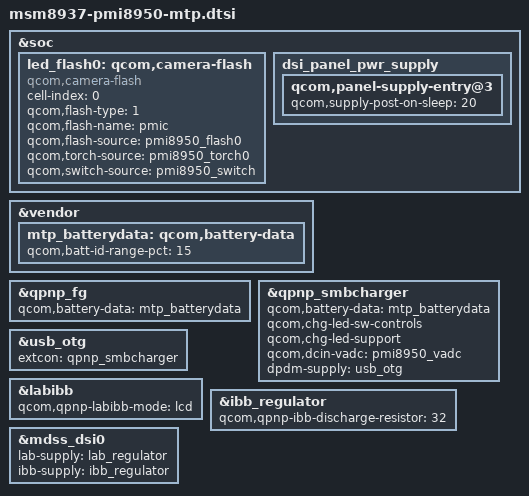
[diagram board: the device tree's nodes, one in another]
/*
 * Copyright (c) 2015-2016, 2018, The Linux Foundation. All rights reserved.
 *
 * This program is free software; you can redistribute it and/or modify
 * it under the terms of the GNU General Public License version 2 and
 * only version 2 as published by the Free Software Foundation.
 *
 * This program is distributed in the hope that it will be useful,
 * but WITHOUT ANY WARRANTY; without even the implied warranty of
 * MERCHANTABILITY or FITNESS FOR A PARTICULAR PURPOSE.  See the
 * GNU General Public License for more details.
 */

#include "pmi8950.dtsi"
#include "msm8937-mtp.dtsi"

&soc {
	led_flash0: qcom,camera-flash {
		cell-index = <0>;
		compatible = "qcom,camera-flash";
		qcom,flash-type = <1>;
		qcom,flash-name = "pmic";
		qcom,flash-source = <&pmi8950_flash0>;
		qcom,torch-source = <&pmi8950_torch0>;
		qcom,switch-source = <&pmi8950_switch>;
	};

	dsi_panel_pwr_supply: dsi_panel_pwr_supply {
		qcom,panel-supply-entry@3 {
			qcom,supply-post-on-sleep = <20>;
		};
	};
};

&vendor {
	mtp_batterydata: qcom,battery-data {
		qcom,batt-id-range-pct = <15>;
		#include "batterydata-oppo16061-sdi-2820mah.dtsi"
		#include "batterydata-oppo16061-lg-2820mah.dtsi"
		#include "batterydata-oppo16061-atl-2820mah.dtsi"
		#include "batterydata-oppo16061-non-std-2820mah.dtsi"
	};
};

&qpnp_fg {
	qcom,battery-data = <&mtp_batterydata>;
};

&qpnp_smbcharger {
	qcom,battery-data = <&mtp_batterydata>;
	qcom,chg-led-sw-controls;
	qcom,chg-led-support;
	qcom,dcin-vadc = <&pmi8950_vadc>;
	dpdm-supply = <&usb_otg>;
};

&usb_otg {
	extcon = <&qpnp_smbcharger>;
};

&labibb {
	status = "ok";
	qcom,qpnp-labibb-mode = "lcd";
};

&ibb_regulator {
	qcom,qpnp-ibb-discharge-resistor = <32>;
};

&mdss_dsi0 {
	lab-supply = <&lab_regulator>;
	ibb-supply = <&ibb_regulator>;
};
